# ESP32-P4 register map
Vendor: ESPRESSIF SYSTEMS (SHANGHAI) CO., LTD.; Series: ESP32 P-Series; File version: 3
CPU: RV32IMAFC r0p0, little endian, no MPU, FPU, 0 interrupt priority bits
Address unit: 32 bits
Registers are 32-bit, read-write, reset 0x0 unless marked. A register's access mark holds for its fields unless they carry their own. Offsets are from the block's base; [hi:lo] are bit positions; {n}, {i} and the like mark numbered series; <NAME> marks a mode.

## EFUSE — eFuse Controller
Base 0x5012D000
{0x0+4i} PGM_DATA{i} (i=0..7) — Represents pgm_data{i}
  [31:0] PGM_DATA — Configures the %sth 32-bit data to be programmed.
{0x20+4i} PGM_CHECK_VALUE{i} (i=0..2) — Represents pgm_check_value{i}
  [31:0] PGM_RS_DATA — Configures the %sth RS code to be programmed.
0x2C RD_WR_DIS ro — Represents rd_wr_dis
  [31:0] WR_DIS — Represents whether programming of individual eFuse memory bit is disabled. For mapping between the bits of this field and the eFuse memory bits, please refer to Table ef{tab:efuse-block0-para} and Table ef{tab:efuse-block-1-10-para}.\\1: Disabled\\0: Enabled\\
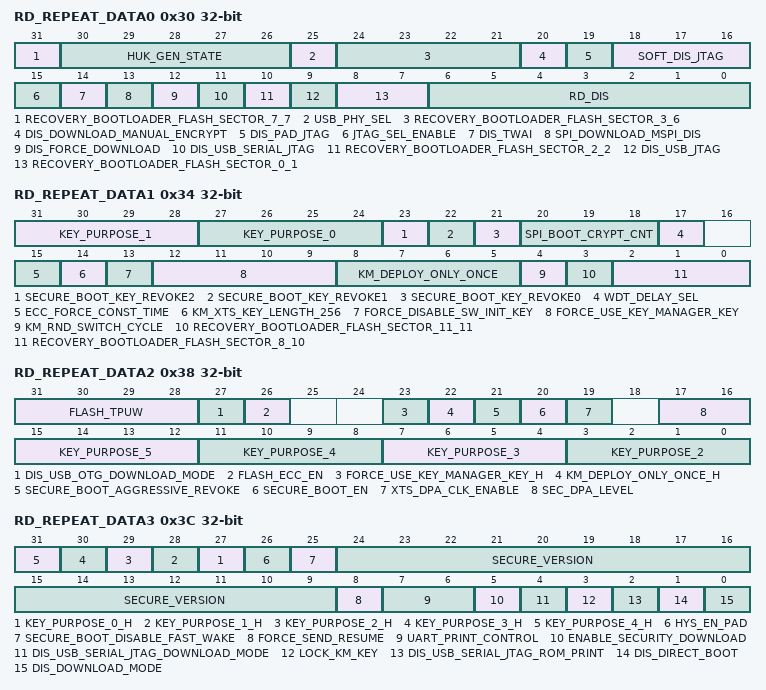
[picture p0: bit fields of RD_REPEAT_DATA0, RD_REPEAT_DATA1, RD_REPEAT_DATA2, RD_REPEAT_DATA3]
0x30 RD_REPEAT_DATA0 ro — Represents rd_repeat_data
  [31] RECOVERY_BOOTLOADER_FLASH_SECTOR_7_7 — Represents the starting flash sector (flash sector size is 0x1000) of the recovery bootloader used by the ROM bootloader If the primary bootloader fails. 0 and 0xFFF - this feature is disabled.
  [30:26] HUK_GEN_STATE — Set the bits to control validation of HUK generate mode. Odd of 1 is invalid, even of 1 is valid.
  [25] USB_PHY_SEL — 0: intphy(gpio24/25) <---> usb_device\\ 1: intphy(26/27) <---> usb_otg11.1: intphy(gpio26/27) <---> usb_device\\ 1: intphy(24/25) <---> usb_otg11.
  [24:21] RECOVERY_BOOTLOADER_FLASH_SECTOR_3_6 — Represents the starting flash sector (flash sector size is 0x1000) of the recovery bootloader used by the ROM bootloader If the primary bootloader fails. 0 and 0xFFF - this feature is disabled.
  [20] DIS_DOWNLOAD_MANUAL_ENCRYPT — Set this bit to disable flash manual encrypt function (except in SPI boot mode).
  [19] DIS_PAD_JTAG — Set this bit to disable JTAG in the hard way. JTAG is disabled permanently.
  [18:16] SOFT_DIS_JTAG — Set odd bits to disable JTAG in the soft way. JTAG can be enabled in HMAC module.
  [15] JTAG_SEL_ENABLE — Set this bit to enable selection between usb_to_jtag and pad_to_jtag through strapping gpio25 when both EFUSE_DIS_PAD_JTAG and EFUSE_DIS_USB_JTAG are equal to 0.
  [14] DIS_TWAI — Set this bit to disable TWAI function.
  [13] SPI_DOWNLOAD_MSPI_DIS — Set this bit to disable accessing MSPI flash/MSPI ram by SYS AXI matrix during boot_mode_download.
  [12] DIS_FORCE_DOWNLOAD — Set this bit to disable the function that forces chip into download mode.
  [11] DIS_USB_SERIAL_JTAG — Set this bit to disable USB-Serial-JTAG.
  [10] RECOVERY_BOOTLOADER_FLASH_SECTOR_2_2 — Represents the starting flash sector (flash sector size is 0x1000) of the recovery bootloader used by the ROM bootloader If the primary bootloader fails. 0 and 0xFFF - this feature is disabled.
  [9] DIS_USB_JTAG — Set this bit to disable function of usb switch to jtag in module of usb device.
  [8:7] RECOVERY_BOOTLOADER_FLASH_SECTOR_0_1 — Represents the starting flash sector (flash sector size is 0x1000) of the recovery bootloader used by the ROM bootloader If the primary bootloader fails. 0 and 0xFFF - this feature is disabled.
  [6:0] RD_DIS — Represents whether reading of individual eFuse block(block4~block10) is disabled or enabled.\\ 1: disabled\\ 0: enabled\\
0x34 RD_REPEAT_DATA1 ro — Represents rd_repeat_data
  [31:28] KEY_PURPOSE_1 — Purpose of Key1.
  [27:24] KEY_PURPOSE_0 — Purpose of Key0.
  [23] SECURE_BOOT_KEY_REVOKE2 — Set this bit to enable revoking third secure boot key.
  [22] SECURE_BOOT_KEY_REVOKE1 — Set this bit to enable revoking second secure boot key.
  [21] SECURE_BOOT_KEY_REVOKE0 — Set this bit to enable revoking first secure boot key.
  [20:18] SPI_BOOT_CRYPT_CNT — Set this bit to enable SPI boot encrypt/decrypt. Odd number of 1: enable. even number of 1: disable.
  [17] WDT_DELAY_SEL — Select lp wdt timeout threshold at startup = initial timeout value * (2 ^ (EFUSE_WDT_DELAY_SEL + 1))
  [15] ECC_FORCE_CONST_TIME — Set this bit to permanently turn on ECC const-time mode.
  [14] KM_XTS_KEY_LENGTH_256 — Set this bit to config flash encryption xts-512 key, else use xts-256 key when using the key manager
  [13] FORCE_DISABLE_SW_INIT_KEY — Set this bit to disable software written init key, and force use efuse_init_key.
  [12:9] FORCE_USE_KEY_MANAGER_KEY — EFUSE_FORCE_USE_KEY_MANAGER_KEY and EFUSE_FORCE_USE_KEY_MANAGER_KEY_H together form one field: {EFUSE_FORCE_USE_KEY_MANAGER_KEY_H, EFUSE_FORCE_USE_KEY_MANAGER_KEY[3:0]}. Set each bit to control whether corresponding key must come from key manager. 1 is true, 0 is false. bit 0: ecsda, bit 1: xts, bit2: hmac, bit3: ds, bit4:psram
  [8:5] KM_DEPLOY_ONLY_ONCE — EFUSE_KM_DEPLOY_ONLY_ONCE and EFUSE_KM_DEPLOY_ONLY_ONCE_H together form one field: {EFUSE_KM_DEPLOY_ONLY_ONCE_H, EFUSE_KM_DEPLOY_ONLY_ONCE[3:0]}. Set each bit to control whether corresponding key can only be deployed once. 1 is true, 0 is false. bit 0: ecsda, bit 1: xts, bit2: hmac, bit3: ds, bit4:psram
  [4] KM_RND_SWITCH_CYCLE — Set the bits to control key manager random number switch cycle. 0: control by register. 1: 8 km clk cycles. 2: 16 km cycles. 3: 32 km cycles
  [3] RECOVERY_BOOTLOADER_FLASH_SECTOR_11_11 — Represents the starting flash sector (flash sector size is 0x1000) of the recovery bootloader used by the ROM bootloader If the primary bootloader fails. 0 and 0xFFF - this feature is disabled.
  [2:0] RECOVERY_BOOTLOADER_FLASH_SECTOR_8_10 — Represents the starting flash sector (flash sector size is 0x1000) of the recovery bootloader used by the ROM bootloader If the primary bootloader fails. 0 and 0xFFF - this feature is disabled.
0x38 RD_REPEAT_DATA2 ro — Represents rd_repeat_data
  [31:28] FLASH_TPUW — Configures flash waiting time after power-up, in unit of ms. When the value less than 15, the waiting time is the configurable value. Otherwise, the waiting time is 30.
  [27] DIS_USB_OTG_DOWNLOAD_MODE — Set this bit to disable download via USB-OTG.
  [26] FLASH_ECC_EN — Set this bit to enable ECC for flash boot.
  [23] FORCE_USE_KEY_MANAGER_KEY_H — EFUSE_FORCE_USE_KEY_MANAGER_KEY and EFUSE_FORCE_USE_KEY_MANAGER_KEY_H together form one field: {EFUSE_FORCE_USE_KEY_MANAGER_KEY_H, EFUSE_FORCE_USE_KEY_MANAGER_KEY[3:0]}. Set each bit to control whether corresponding key must come from key manager. 1 is true, 0 is false. bit 0: ecsda, bit 1: xts, bit2: hmac, bit3: ds, bit4:psram
  [22] KM_DEPLOY_ONLY_ONCE_H — EFUSE_KM_DEPLOY_ONLY_ONCE and EFUSE_KM_DEPLOY_ONLY_ONCE_H together form one field: {EFUSE_KM_DEPLOY_ONLY_ONCE_H, EFUSE_KM_DEPLOY_ONLY_ONCE[3:0]}. Set each bit to control whether corresponding key can only be deployed once. 1 is true, 0 is false. bit 0: ecsda, bit 1: xts, bit2: hmac, bit3: ds, bit4:psram
  [21] SECURE_BOOT_AGGRESSIVE_REVOKE — Set this bit to enable revoking aggressive secure boot.
  [20] SECURE_BOOT_EN — Set this bit to enable secure boot.
  [19] XTS_DPA_CLK_ENABLE — Sets this bit to enable xts clock anti-dpa attack function.
  [17:16] SEC_DPA_LEVEL — Configures the clock random divide mode to determine the dpa secure level
  [4n-5:4n-8] KEY_PURPOSE_{n} (n=2..5) — Purpose of Key{n}.
0x3C RD_REPEAT_DATA3 ro — Represents rd_repeat_data
  [n+27] KEY_PURPOSE_{n}_H (n=0..4) — Purpose of Key{n}. The 5-th bit.
  [26] HYS_EN_PAD — Set bits to enable hysteresis function of PAD0~27
  [25] SECURE_BOOT_DISABLE_FAST_WAKE — Represents whether secure boot do fast verification on wake is disabled. 0: enabled 1: disabled
  [24:9] SECURE_VERSION — Secure version used by ESP-IDF anti-rollback feature.
  [8] FORCE_SEND_RESUME — Set this bit to force ROM code to send a resume command during SPI boot.
  [7:6] UART_PRINT_CONTROL — Set the type of UART printing, 00: force enable printing, 01: enable printing when GPIO8 is reset at low level, 10: enable printing when GPIO8 is reset at high level, 11: force disable printing
  [5] ENABLE_SECURITY_DOWNLOAD — Set this bit to enable security download mode.
  [4] DIS_USB_SERIAL_JTAG_DOWNLOAD_MODE — Set this bit to disable the USB-Serial-JTAG download function.
  [3] LOCK_KM_KEY — set this bit to lock the key manager key after deploy
  [2] DIS_USB_SERIAL_JTAG_ROM_PRINT — Set this bit to disable USB-Serial-JTAG print during rom boot.
  [1] DIS_DIRECT_BOOT — Set this bit to disable direct boot mode
  [0] DIS_DOWNLOAD_MODE — Set this bit to disable download mode (boot_mode[3:0] = 0, 1, 2, 4, 5, 6, 7).
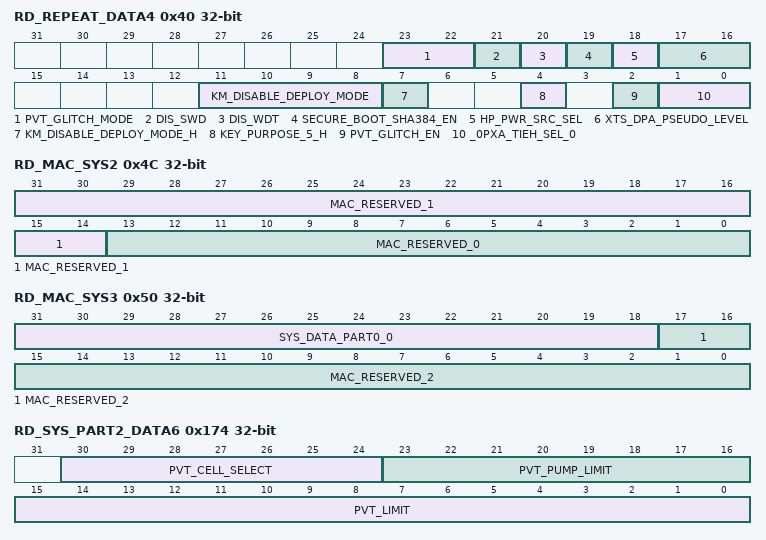
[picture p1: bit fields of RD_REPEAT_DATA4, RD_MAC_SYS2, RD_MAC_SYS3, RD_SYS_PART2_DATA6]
0x40 RD_REPEAT_DATA4 ro — Represents rd_repeat_data
  [23:22] PVT_GLITCH_MODE — Use to configure glitch mode
  [21] DIS_SWD — Set bit to disable super-watchdog
  [20] DIS_WDT — Set this bit to disable watch dog.
  [19] SECURE_BOOT_SHA384_EN — Represents whether secure boot using SHA-384 is enabled. 0: disable 1: enable
  [18] HP_PWR_SRC_SEL — HP system power source select. 0:LDO 1: DCDC
  [17:16] XTS_DPA_PSEUDO_LEVEL — Sets this bit to control the xts pseudo-round anti-dpa attack function. 0: controlled by register. 1-3: the higer the value is, the more pseudo-rounds are inserted to the xts-aes calculation
  [11:8] KM_DISABLE_DEPLOY_MODE — EFUSE_KM_DISABLE_DEPLOY_MODE and EFUSE_KM_DISABLE_DEPLOY_MODE_H together form one field: {EFUSE_KM_DISABLE_DEPLOY_MODE_H, EFUSE_KM_DISABLE_DEPLOY_MODE[3:0]}. Set each bit to control whether corresponding key's deploy mode of new value deployment is disabled. 1 is true, 0 is false. bit 0: ecsda, bit 1: xts, bit2: hmac, bit3: ds, bit4:psram
  [7] KM_DISABLE_DEPLOY_MODE_H — EFUSE_KM_DISABLE_DEPLOY_MODE and EFUSE_KM_DISABLE_DEPLOY_MODE_H together form one field: {EFUSE_KM_DISABLE_DEPLOY_MODE_H, EFUSE_KM_DISABLE_DEPLOY_MODE[3:0]}. Set each bit to control whether corresponding key's deploy mode of new value deployment is disabled. 1 is true, 0 is false. bit 0: ecsda, bit 1: xts, bit2: hmac, bit3: ds, bit4:psram
  [4] KEY_PURPOSE_5_H — Purpose of Key5. The 5-th bit.
  [2] PVT_GLITCH_EN — Represents whether to enable PVT power glitch monitor function.\\1:Enable. \\0:Disable
  [1:0] _0PXA_TIEH_SEL_0 — Output LDO VO0 tieh source select. 0: 1'b1 1: sdmmc1 2: reg 3:sdmmc0
0x44 RD_MAC_SYS0 ro — Represents rd_mac_sys
  [31:0] MAC_0 — Represents MAC address. Low 32-bit.
0x48 RD_MAC_SYS1 ro — Represents rd_mac_sys
  [15:0] MAC_1 — Represents MAC address. High 16-bit.
0x4C RD_MAC_SYS2 ro — Represents rd_mac_sys
  [31:14] MAC_RESERVED_1 — Reserved.
  [13:0] MAC_RESERVED_0 — Reserved.
0x50 RD_MAC_SYS3 ro — Represents rd_mac_sys
  [31:18] SYS_DATA_PART0_0 — Represents the first 14-bit of zeroth part of system data.
  [17:0] MAC_RESERVED_2 — Reserved.
0x54 RD_MAC_SYS4 ro — Represents rd_mac_sys
  [31:0] SYS_DATA_PART0_1 — Represents the second 32-bit of zeroth part of system data.
0x58 RD_MAC_SYS5 ro — Represents rd_mac_sys
  [31:0] SYS_DATA_PART0_2 — Represents the third 32-bit of zeroth part of system data.
{0x5C+4i} RD_SYS_PART1_DATA{i} (i=0..7) ro — Represents rd_sys_part1_data{i}
  [31:0] SYS_DATA_PART1 — Represents the zeroth 32-bit of first part of system data.
{0x7C+4i} RD_USR_DATA{i} (i=0..7) ro — Represents rd_usr_data{i}
  [31:0] USR_DATA — Represents the zeroth 32-bit of block3 (user).
{0x9C+4i} RD_KEY0_DATA{i} (i=0..7) ro — Represents rd_key0_data{i}
  [31:0] KEY0_DATA — Represents the zeroth 32-bit of key0.
{0xBC+4i} RD_KEY1_DATA{i} (i=0..7) ro — Represents rd_key1_data{i}
  [31:0] KEY1_DATA — Represents the zeroth 32-bit of key1.
{0xDC+4i} RD_KEY2_DATA{i} (i=0..7) ro — Represents rd_key2_data{i}
  [31:0] KEY2_DATA — Represents the zeroth 32-bit of key2.
{0xFC+4i} RD_KEY3_DATA{i} (i=0..7) ro — Represents rd_key3_data{i}
  [31:0] KEY3_DATA — Represents the zeroth 32-bit of key3.
{0x11C+4i} RD_KEY4_DATA{i} (i=0..7) ro — Represents rd_key4_data{i}
  [31:0] KEY4_DATA — Represents the zeroth 32-bit of key4.
{0x13C+4i} RD_KEY5_DATA{i} (i=0..7) ro — Represents rd_key5_data{i}
  [31:0] KEY5_DATA — Represents the zeroth 32-bit of key5.
0x15C RD_SYS_PART2_DATA0 ro — Represents rd_sys_part2_data
  [31:0] SYS_DATA_PART2_0 — Represents the first 32-bit of second part of system data.
0x160 RD_SYS_PART2_DATA1 ro — Represents rd_sys_part2_data
  [31:0] SYS_DATA_PART2_1 — Represents the first 32-bit of second part of system data.
0x164 RD_SYS_PART2_DATA2 ro — Represents rd_sys_part2_data
  [31:0] SYS_DATA_PART2_2 — Represents the second 32-bit of second part of system data.
0x168 RD_SYS_PART2_DATA3 ro — Represents rd_sys_part2_data
  [31:0] SYS_DATA_PART2_3 — Represents the third 32-bit of second part of system data.
0x16C RD_SYS_PART2_DATA4 ro — Represents rd_sys_part2_data
  [31:0] SYS_DATA_PART2_4 — Represents the fourth 32-bit of second part of system data.
0x170 RD_SYS_PART2_DATA5 ro — Represents rd_sys_part2_data
  [31:0] SYS_DATA_PART2_5 — Represents the fifth 32-bit of second part of system data.
0x174 RD_SYS_PART2_DATA6 ro — Represents rd_sys_part2_data
  [30:24] PVT_CELL_SELECT — Power glitch monitor PVT cell select.
  [23:16] PVT_PUMP_LIMIT — Use to configure voltage monitor limit for charge pump
  [15:0] PVT_LIMIT — Power glitch monitor threthold.
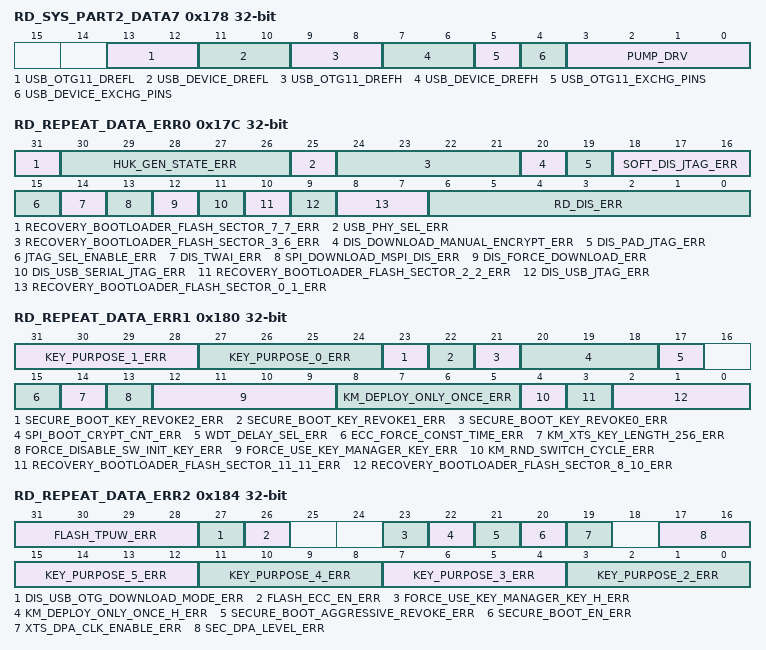
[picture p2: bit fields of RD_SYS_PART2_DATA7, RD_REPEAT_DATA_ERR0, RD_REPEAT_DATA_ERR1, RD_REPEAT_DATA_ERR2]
0x178 RD_SYS_PART2_DATA7 ro — Represents rd_sys_part2_data
  [13:12] USB_OTG11_DREFL — usb intphy of usb otg11 single-end input low threshold, 0.8V to 1.04V. step by 80mV.
  [11:10] USB_DEVICE_DREFL — usb intphy of usb device single-end input low threshold, 0.8V to 1.04V. step by 80mV.
  [9:8] USB_OTG11_DREFH — usb intphy of usb otg11 single-end input high threshold, 1.76V to 2V. step by 80mV.
  [7:6] USB_DEVICE_DREFH — usb intphy of usb device single-end input high threshold, 1.76V to 2V. step by 80mV.
  [5] USB_OTG11_EXCHG_PINS — Enable usb otg11 exchange pins of D+ and D-.
  [4] USB_DEVICE_EXCHG_PINS — Enable usb device exchange pins of D+ and D-.
  [3:0] PUMP_DRV — Use to configure charge pump voltage gain
0x17C RD_REPEAT_DATA_ERR0 ro — Represents rd_repeat_data_err
  [31] RECOVERY_BOOTLOADER_FLASH_SECTOR_7_7_ERR — Represents the programming error of EFUSE_RECOVERY_BOOTLOADER_FLASH_SECTOR_7_7
  [30:26] HUK_GEN_STATE_ERR — Represents the programming error of EFUSE_HUK_GEN_STATE
  [25] USB_PHY_SEL_ERR — Represents the programming error of EFUSE_USB_PHY_SEL
  [24:21] RECOVERY_BOOTLOADER_FLASH_SECTOR_3_6_ERR — Represents the programming error of EFUSE_RECOVERY_BOOTLOADER_FLASH_SECTOR_3_6
  [20] DIS_DOWNLOAD_MANUAL_ENCRYPT_ERR — Represents the programming error of EFUSE_DIS_DOWNLOAD_MANUAL_ENCRYPT
  [19] DIS_PAD_JTAG_ERR — Represents the programming error of EFUSE_DIS_PAD_JTAG
  [18:16] SOFT_DIS_JTAG_ERR — Represents the programming error of EFUSE_SOFT_DIS_JTAG
  [15] JTAG_SEL_ENABLE_ERR — Represents the programming error of EFUSE_JTAG_SEL_ENABLE
  [14] DIS_TWAI_ERR — Represents the programming error of EFUSE_DIS_TWAI
  [13] SPI_DOWNLOAD_MSPI_DIS_ERR — Represents the programming error of EFUSE_SPI_DOWNLOAD_MSPI_DIS
  [12] DIS_FORCE_DOWNLOAD_ERR — Represents the programming error of EFUSE_DIS_FORCE_DOWNLOAD
  [11] DIS_USB_SERIAL_JTAG_ERR — Represents the programming error of EFUSE_DIS_USB_SERIAL_JTAG
  [10] RECOVERY_BOOTLOADER_FLASH_SECTOR_2_2_ERR — Represents the programming error of EFUSE_RECOVERY_BOOTLOADER_FLASH_SECTOR_2_2
  [9] DIS_USB_JTAG_ERR — Represents the programming error of EFUSE_DIS_USB_JTAG
  [8:7] RECOVERY_BOOTLOADER_FLASH_SECTOR_0_1_ERR — Represents the programming error of EFUSE_RECOVERY_BOOTLOADER_FLASH_SECTOR_0_1
  [6:0] RD_DIS_ERR — Represents the programming error of EFUSE_RD_DIS
0x180 RD_REPEAT_DATA_ERR1 ro — Represents rd_repeat_data_err
  [31:28] KEY_PURPOSE_1_ERR — Represents the programming error of EFUSE_KEY_PURPOSE_1
  [27:24] KEY_PURPOSE_0_ERR — Represents the programming error of EFUSE_KEY_PURPOSE_0
  [23] SECURE_BOOT_KEY_REVOKE2_ERR — Represents the programming error of EFUSE_SECURE_BOOT_KEY_REVOKE2
  [22] SECURE_BOOT_KEY_REVOKE1_ERR — Represents the programming error of EFUSE_SECURE_BOOT_KEY_REVOKE1
  [21] SECURE_BOOT_KEY_REVOKE0_ERR — Represents the programming error of EFUSE_SECURE_BOOT_KEY_REVOKE0
  [20:18] SPI_BOOT_CRYPT_CNT_ERR — Represents the programming error of EFUSE_SPI_BOOT_CRYPT_CNT
  [17] WDT_DELAY_SEL_ERR — Represents the programming error of EFUSE_WDT_DELAY_SEL
  [15] ECC_FORCE_CONST_TIME_ERR — Represents the programming error of EFUSE_ECC_FORCE_CONST_TIME
  [14] KM_XTS_KEY_LENGTH_256_ERR — Represents the programming error of EFUSE_KM_XTS_KEY_LENGTH_256
  [13] FORCE_DISABLE_SW_INIT_KEY_ERR — Represents the programming error of EFUSE_FORCE_DISABLE_SW_INIT_KEY
  [12:9] FORCE_USE_KEY_MANAGER_KEY_ERR — Represents the programming error of EFUSE_FORCE_USE_KEY_MANAGER_KEY
  [8:5] KM_DEPLOY_ONLY_ONCE_ERR — Represents the programming error of EFUSE_KM_DEPLOY_ONLY_ONCE
  [4] KM_RND_SWITCH_CYCLE_ERR — Represents the programming error of EFUSE_KM_RND_SWITCH_CYCLE
  [3] RECOVERY_BOOTLOADER_FLASH_SECTOR_11_11_ERR — Represents the programming error of EFUSE_RECOVERY_BOOTLOADER_FLASH_SECTOR_11_11
  [2:0] RECOVERY_BOOTLOADER_FLASH_SECTOR_8_10_ERR — Represents the programming error of EFUSE_RECOVERY_BOOTLOADER_FLASH_SECTOR_8_10
0x184 RD_REPEAT_DATA_ERR2 ro — Represents rd_repeat_data_err
  [31:28] FLASH_TPUW_ERR — Represents the programming error of EFUSE_FLASH_TPUW
  [27] DIS_USB_OTG_DOWNLOAD_MODE_ERR — Represents the programming error of EFUSE_DIS_USB_OTG_DOWNLOAD_MODE
  [26] FLASH_ECC_EN_ERR — Represents the programming error of EFUSE_FLASH_ECC_EN
  [23] FORCE_USE_KEY_MANAGER_KEY_H_ERR — Represents the programming error of EFUSE_FORCE_USE_KEY_MANAGER_KEY_H
  [22] KM_DEPLOY_ONLY_ONCE_H_ERR — Represents the programming error of EFUSE_KM_DEPLOY_ONLY_ONCE_H
  [21] SECURE_BOOT_AGGRESSIVE_REVOKE_ERR — Represents the programming error of EFUSE_SECURE_BOOT_AGGRESSIVE_REVOKE
  [20] SECURE_BOOT_EN_ERR — Represents the programming error of EFUSE_SECURE_BOOT_EN
  [19] XTS_DPA_CLK_ENABLE_ERR — Represents the programming error of EFUSE_XTS_DPA_CLK_ENABLE
  [17:16] SEC_DPA_LEVEL_ERR — Represents the programming error of EFUSE_SEC_DPA_LEVEL
  [4n-5:4n-8] KEY_PURPOSE_{n}_ERR (n=2..5) — Represents the programming error of EFUSE_KEY_PURPOSE_{n}
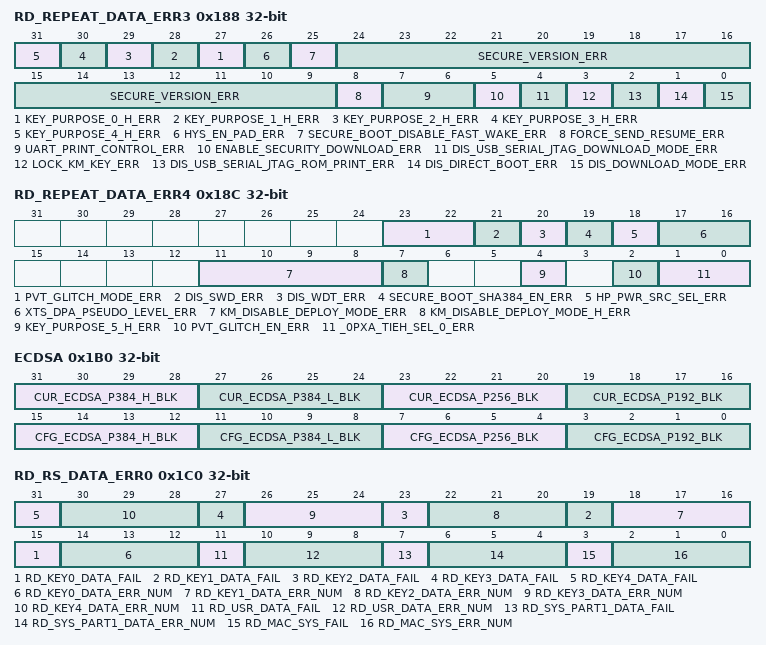
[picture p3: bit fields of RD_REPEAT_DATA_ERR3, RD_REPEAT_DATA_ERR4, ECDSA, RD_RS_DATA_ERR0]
0x188 RD_REPEAT_DATA_ERR3 ro — Represents rd_repeat_data_err
  [n+27] KEY_PURPOSE_{n}_H_ERR (n=0..4) — Represents the programming error of EFUSE_KEY_PURPOSE_{n}_H
  [26] HYS_EN_PAD_ERR — Represents the programming error of EFUSE_HYS_EN_PAD
  [25] SECURE_BOOT_DISABLE_FAST_WAKE_ERR — Represents the programming error of EFUSE_SECURE_BOOT_DISABLE_FAST_WAKE
  [24:9] SECURE_VERSION_ERR — Represents the programming error of EFUSE_SECURE_VERSION
  [8] FORCE_SEND_RESUME_ERR — Represents the programming error of EFUSE_FORCE_SEND_RESUME
  [7:6] UART_PRINT_CONTROL_ERR — Represents the programming error of EFUSE_UART_PRINT_CONTROL
  [5] ENABLE_SECURITY_DOWNLOAD_ERR — Represents the programming error of EFUSE_ENABLE_SECURITY_DOWNLOAD
  [4] DIS_USB_SERIAL_JTAG_DOWNLOAD_MODE_ERR — Represents the programming error of EFUSE_DIS_USB_SERIAL_JTAG_DOWNLOAD_MODE
  [3] LOCK_KM_KEY_ERR — Represents the programming error of EFUSE_LOCK_KM_KEY
  [2] DIS_USB_SERIAL_JTAG_ROM_PRINT_ERR — Represents the programming error of EFUSE_DIS_USB_SERIAL_JTAG_ROM_PRINT
  [1] DIS_DIRECT_BOOT_ERR — Represents the programming error of EFUSE_DIS_DIRECT_BOOT
  [0] DIS_DOWNLOAD_MODE_ERR — Represents the programming error of EFUSE_DIS_DOWNLOAD_MODE
0x18C RD_REPEAT_DATA_ERR4 ro — Represents rd_repeat_data_err
  [23:22] PVT_GLITCH_MODE_ERR — Represents the programming error of EFUSE_PVT_GLITCH_MODE
  [21] DIS_SWD_ERR — Represents the programming error of EFUSE_DIS_SWD
  [20] DIS_WDT_ERR — Represents the programming error of EFUSE_DIS_WDT
  [19] SECURE_BOOT_SHA384_EN_ERR — Represents the programming error of EFUSE_SECURE_BOOT_SHA384_EN
  [18] HP_PWR_SRC_SEL_ERR — Represents the programming error of EFUSE_HP_PWR_SRC_SEL
  [17:16] XTS_DPA_PSEUDO_LEVEL_ERR — Represents the programming error of EFUSE_XTS_DPA_PSEUDO_LEVEL
  [11:8] KM_DISABLE_DEPLOY_MODE_ERR — Represents the programming error of EFUSE_KM_DISABLE_DEPLOY_MODE
  [7] KM_DISABLE_DEPLOY_MODE_H_ERR — Represents the programming error of EFUSE_KM_DISABLE_DEPLOY_MODE_H
  [4] KEY_PURPOSE_5_H_ERR — Represents the programming error of EFUSE_KEY_PURPOSE_5_H
  [2] PVT_GLITCH_EN_ERR — Represents the programming error of EFUSE_PVT_GLITCH_EN
  [1:0] _0PXA_TIEH_SEL_0_ERR — Represents the programming error of EFUSE_0PXA_TIEH_SEL_0
0x1B0 ECDSA access per field — eFuse status register.
  [31:28] CUR_ECDSA_P384_H_BLK ro — Represents which block is used for ECDSA P384 key high part output.
  [27:24] CUR_ECDSA_P384_L_BLK ro — Represents which block is used for ECDSA P384 key low part output.
  [23:20] CUR_ECDSA_P256_BLK ro — Represents which block is used for ECDSA P256 key output.
  [19:16] CUR_ECDSA_P192_BLK ro — Represents which block is used for ECDSA P192 key output.
  [15:12] CFG_ECDSA_P384_H_BLK rw — Configures which block to use for ECDSA P256 key high part output.
  [11:8] CFG_ECDSA_P384_L_BLK rw — Configures which block to use for ECDSA P384 key low part output.
  [7:4] CFG_ECDSA_P256_BLK rw — Configures which block to use for ECDSA P256 key output.
  [3:0] CFG_ECDSA_P192_BLK rw — Configures which block to use for ECDSA P192 key output.
0x1C0 RD_RS_DATA_ERR0 ro — Represents rd_rs_data_err
  [4n+15] RD_KEY{n}_DATA_FAIL (n=0..4) — Represents error status of register.\\0: Means no failure and that the data of rd_key{n}_data is reliable\\ 1: Means that programming rd_key{n}_data failed and the number of error bytes is over 6.
  [4n+14:4n+12] RD_KEY{n}_DATA_ERR_NUM (n=0..4) — Represents the error number of registers.\\The value of this signal means the number of error bytes in rd_key{n}_data
  [11] RD_USR_DATA_FAIL — Represents error status of register.\\0: Means no failure and that the data of rd_usr_data is reliable\\ 1: Means that programming rd_usr_data failed and the number of error bytes is over 6.
  [10:8] RD_USR_DATA_ERR_NUM — Represents the error number of registers.\\The value of this signal means the number of error bytes in rd_usr_data
  [7] RD_SYS_PART1_DATA_FAIL — Represents error status of register.\\0: Means no failure and that the data of rd_sys_part1_data is reliable\\ 1: Means that programming rd_sys_part1_data failed and the number of error bytes is over 6.
  [6:4] RD_SYS_PART1_DATA_ERR_NUM — Represents the error number of registers.\\The value of this signal means the number of error bytes in rd_sys_part1_data
  [3] RD_MAC_SYS_FAIL — Represents error status of register.\\0: Means no failure and that the data of rd_mac_sys is reliable\\ 1: Means that programming rd_mac_sys failed and the number of error bytes is over 6.
  [2:0] RD_MAC_SYS_ERR_NUM — Represents the error number of registers.\\The value of this signal means the number of error bytes in rd_mac_sys
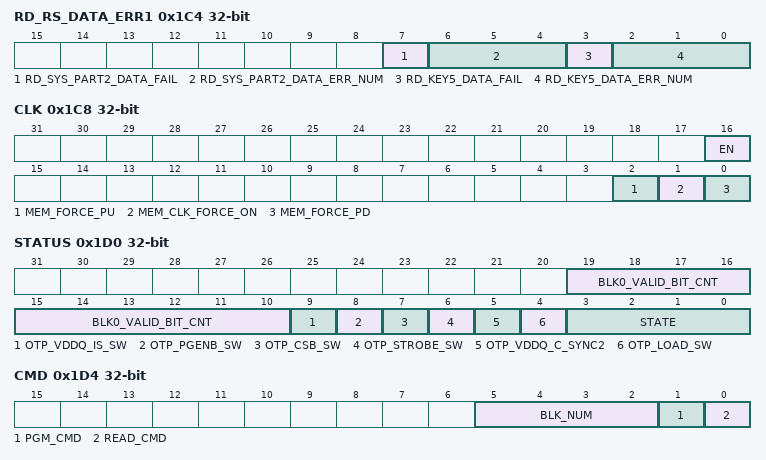
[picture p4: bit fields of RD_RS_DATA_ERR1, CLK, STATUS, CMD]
0x1C4 RD_RS_DATA_ERR1 ro — Represents rd_rs_data_err
  [7] RD_SYS_PART2_DATA_FAIL — Represents error status of register.\\0: Means no failure and that the data of rd_sys_part2_data is reliable\\ 1: Means that programming rd_sys_part2_data failed and the number of error bytes is over 6.
  [6:4] RD_SYS_PART2_DATA_ERR_NUM — Represents the error number of registers.\\The value of this signal means the number of error bytes in rd_sys_part2_data
  [3] RD_KEY5_DATA_FAIL — Represents error status of register.\\0: Means no failure and that the data of rd_key5_data is reliable\\ 1: Means that programming rd_key5_data failed and the number of error bytes is over 6.
  [2:0] RD_KEY5_DATA_ERR_NUM — Represents the error number of registers.\\The value of this signal means the number of error bytes in rd_key5_data
0x1C8 CLK — eFuse clcok configuration register.
  [16] EN — Set this bit to force enable eFuse register configuration clock signal.
  [2] MEM_FORCE_PU — Set this bit to force eFuse SRAM into working mode.
  [1] MEM_CLK_FORCE_ON — Set this bit and force to activate clock signal of eFuse SRAM.
  [0] MEM_FORCE_PD — Set this bit to force eFuse SRAM into power-saving mode.
0x1CC CONF — eFuse operation mode configuraiton register
  [15:0] OP_CODE — 0x5A5A: programming operation command 0x5AA5: read operation command.
0x1D0 STATUS ro — eFuse status register.
  [19:10] BLK0_VALID_BIT_CNT — Indicates the number of block valid bit.
  [9] OTP_VDDQ_IS_SW — The value of OTP_VDDQ_IS_SW.
  [8] OTP_PGENB_SW — The value of OTP_PGENB_SW.
  [7] OTP_CSB_SW — The value of OTP_CSB_SW.
  [6] OTP_STROBE_SW — The value of OTP_STROBE_SW.
  [5] OTP_VDDQ_C_SYNC2 — The value of OTP_VDDQ_C_SYNC2.
  [4] OTP_LOAD_SW — The value of OTP_LOAD_SW.
  [3:0] STATE — Indicates the state of the eFuse state machine.
0x1D4 CMD — eFuse command register.
  [5:2] BLK_NUM — The serial number of the block to be programmed. Value 0-10 corresponds to block number 0-10, respectively.
  [1] PGM_CMD — Set this bit to send programming command.
  [0] READ_CMD — Set this bit to send read command.
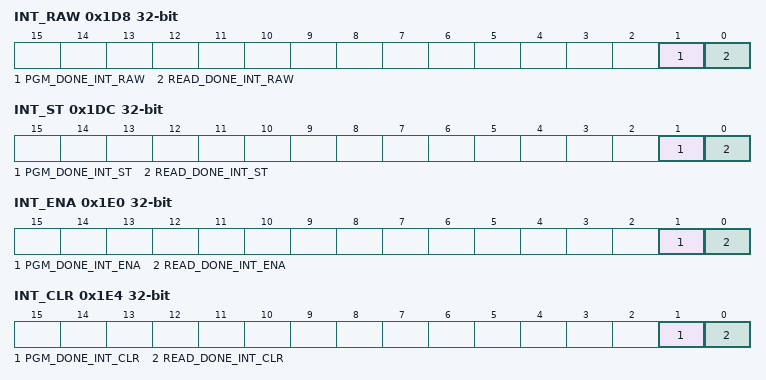
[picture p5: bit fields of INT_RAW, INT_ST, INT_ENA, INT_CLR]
0x1D8 INT_RAW ro — eFuse raw interrupt register.
  [1] PGM_DONE_INT_RAW — The raw bit signal for pgm_done interrupt.
  [0] READ_DONE_INT_RAW — The raw bit signal for read_done interrupt.
0x1DC INT_ST ro — eFuse interrupt status register.
  [1] PGM_DONE_INT_ST — The status signal for pgm_done interrupt.
  [0] READ_DONE_INT_ST — The status signal for read_done interrupt.
0x1E0 INT_ENA — eFuse interrupt enable register.
  [1] PGM_DONE_INT_ENA — The enable signal for pgm_done interrupt.
  [0] READ_DONE_INT_ENA — The enable signal for read_done interrupt.
0x1E4 INT_CLR wo — eFuse interrupt clear register.
  [1] PGM_DONE_INT_CLR — The clear signal for pgm_done interrupt.
  [0] READ_DONE_INT_CLR — The clear signal for read_done interrupt.
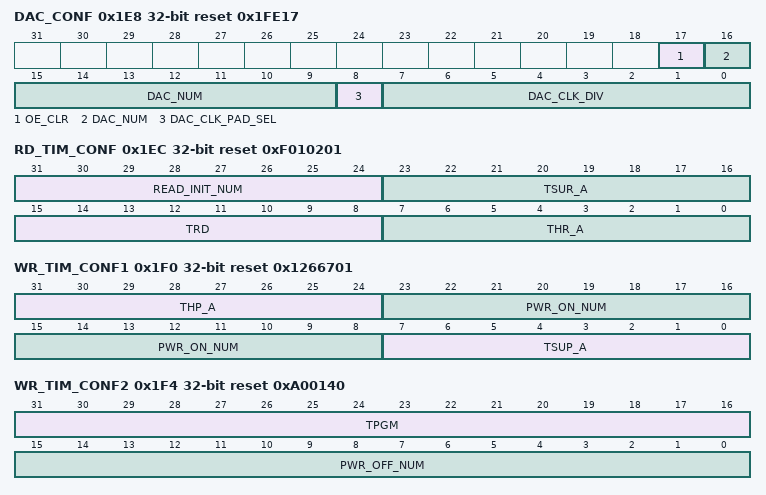
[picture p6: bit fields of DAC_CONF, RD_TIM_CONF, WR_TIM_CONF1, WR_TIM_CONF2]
0x1E8 DAC_CONF reset 0x1FE17 — Controls the eFuse programming voltage.
  [17] OE_CLR — Reduces the power supply of the programming voltage.
  [16:9] DAC_NUM — Controls the rising period of the programming voltage.
  [8] DAC_CLK_PAD_SEL — Don't care.
  [7:0] DAC_CLK_DIV — Controls the division factor of the rising clock of the programming voltage.
0x1EC RD_TIM_CONF reset 0xF010201 — Configures read timing parameters.
  [31:24] READ_INIT_NUM — Configures the waiting time of reading eFuse memory.
  [23:16] TSUR_A — Configures the read setup time.
  [15:8] TRD — Configures the read time.
  [7:0] THR_A — Configures the read hold time.
0x1F0 WR_TIM_CONF1 reset 0x1266701 — Configurarion register 1 of eFuse programming timing parameters.
  [31:24] THP_A — Configures the programming hold time.
  [23:8] PWR_ON_NUM — Configures the power up time for VDDQ.
  [7:0] TSUP_A — Configures the programming setup time.
0x1F4 WR_TIM_CONF2 reset 0xA00140 — Configurarion register 2 of eFuse programming timing parameters.
  [31:16] TPGM — Configures the active programming time.
  [15:0] PWR_OFF_NUM — Configures the power outage time for VDDQ.
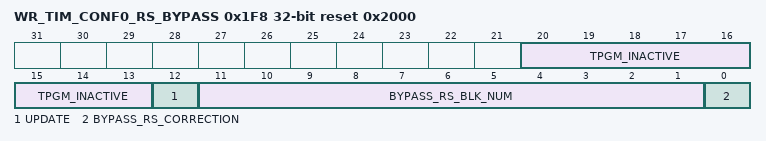
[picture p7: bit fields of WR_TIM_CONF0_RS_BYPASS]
0x1F8 WR_TIM_CONF0_RS_BYPASS access per field reset 0x2000 — Configurarion register0 of eFuse programming time parameters and rs bypass operation.
  [20:13] TPGM_INACTIVE rw — Configures the inactive programming time.
  [12] UPDATE wo — Set this bit to update multi-bit register signals.
  [11:1] BYPASS_RS_BLK_NUM rw — Configures block number of programming twice operation.
  [0] BYPASS_RS_CORRECTION rw — Set this bit to bypass reed solomon correction step.
0x1FC DATE reset 0x2502190 — eFuse version register.
  [27:0] DATE — Stores eFuse version.
0x800 APB2OTP_WR_DIS ro — eFuse apb2otp block0 data register1.
  [31:0] APB2OTP_BLOCK0_WR_DIS — Otp block0 write disable data.
{0x800+4i} APB2OTP_BLK0_BACKUP1_W{i} ro (i=1..5) — eFuse apb2otp block0 data register{i+1}.
  [31:0] APB2OTP_BLOCK0_BACKUP1_W{i} — Otp block0 backup1 word{i} data.
{0x814+4i} APB2OTP_BLK0_BACKUP2_W{i} ro (i=1..5) — eFuse apb2otp block0 data register{i+6}.
  [31:0] APB2OTP_BLOCK0_BACKUP2_W{i} — Otp block0 backup2 word{i} data.
{0x828+4i} APB2OTP_BLK0_BACKUP3_W{i} ro (i=1..5) — eFuse apb2otp block0 data register{i+11}.
  [31:0] APB2OTP_BLOCK0_BACKUP3_W{i} — Otp block0 backup3 word{i} data.
{0x83C+4i} APB2OTP_BLK0_BACKUP4_W{i} ro (i=1..5) — eFuse apb2otp block0 data register{i+16}.
  [31:0] APB2OTP_BLOCK0_BACKUP4_W{i} — Otp block0 backup4 word{i} data.
{0x850+4i} APB2OTP_BLK1_W{i} ro (i=1..9) — eFuse apb2otp block1 data register{i}.
  [31:0] APB2OTP_BLOCK1_W{i} — Otp block1 word{i} data.
{0x874+4i} APB2OTP_BLK2_W{i} ro (i=1..11) — eFuse apb2otp block2 data register{i}.
  [31:0] APB2OTP_BLOCK2_W{i} — Otp block2 word{i} data.
{0x8A0+4i} APB2OTP_BLK3_W{i} ro (i=1..11) — eFuse apb2otp block3 data register{i}.
  [31:0] APB2OTP_BLOCK3_W{i} — Otp block3 word{i} data.
{0x8CC+4i} APB2OTP_BLK4_W{i} ro (i=1..9) — eFuse apb2otp block4 data register{i}.
  [31:0] APB2OTP_BLOCK4_W{i} — Otp block4 word{i} data.
0x8F4 APB2OTP_BLK4_W10 ro — eFuse apb2otp block4 data registe10.
  [31:0] APB2OTP_BLOCK4_W10 — Otp block4 word10 data.
0x8F8 APB2OTP_BLK4_W11 ro — eFuse apb2otp block4 data register11.
  [31:0] APB2OTP_BLOCK4_W11 — Otp block4 word11 data.
{0x8F8+4i} APB2OTP_BLK5_W{i} ro (i=1..11) — eFuse apb2otp block5 data register{i}.
  [31:0] APB2OTP_BLOCK5_W{i} — Otp block5 word{i} data.
{0x924+4i} APB2OTP_BLK6_W{i} ro (i=1..11) — eFuse apb2otp block6 data register{i}.
  [31:0] APB2OTP_BLOCK6_W{i} — Otp block6 word{i} data.
{0x950+4i} APB2OTP_BLK7_W{i} ro (i=1..11) — eFuse apb2otp block7 data register{i}.
  [31:0] APB2OTP_BLOCK7_W{i} — Otp block7 word{i} data.
{0x97C+4i} APB2OTP_BLK8_W{i} ro (i=1..11) — eFuse apb2otp block8 data register{i}.
  [31:0] APB2OTP_BLOCK8_W{i} — Otp block8 word{i} data.
{0x9A8+4i} APB2OTP_BLK9_W{i} ro (i=1..11) — eFuse apb2otp block9 data register{i}.
  [31:0] APB2OTP_BLOCK9_W{i} — Otp block9 word{i} data.
{0x9D4+4i} APB2OTP_BLK10_W{i} ro (i=1..9) — eFuse apb2otp block10 data register{i}.
  [31:0] APB2OTP_BLOCK10_W{i} — Otp block10 word{i} data.
0x9FC APB2OTP_BLK10_W10 ro — eFuse apb2otp block10 data register10.
  [31:0] APB2OTP_BLOCK19_W10 — Otp block10 word10 data.
0xA00 APB2OTP_BLK10_W11 ro — eFuse apb2otp block10 data register11.
  [31:0] APB2OTP_BLOCK10_W11 — Otp block10 word11 data.
0xA08 APB2OTP_EN — eFuse apb2otp enable configuration register.
  [0] APB2OTP_APB2OTP_EN — Apb2otp mode enable signal.
